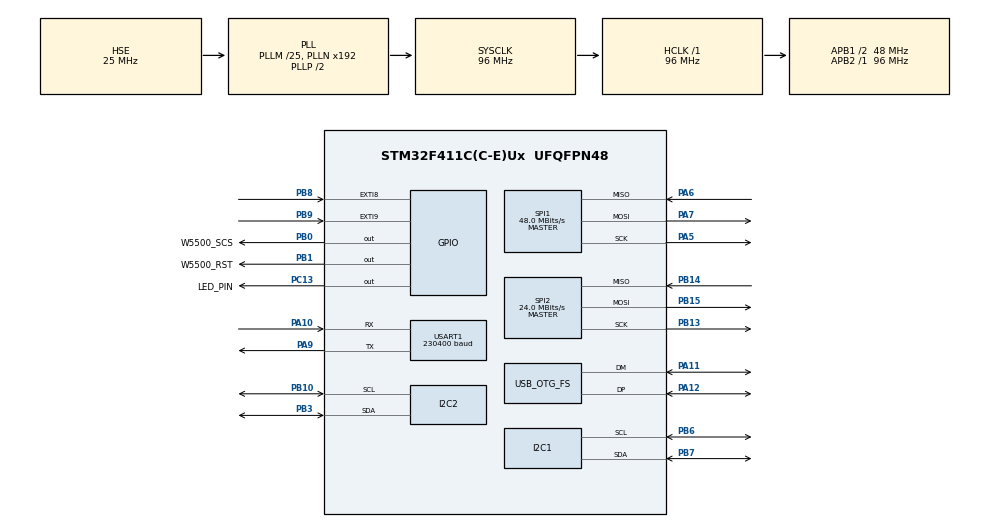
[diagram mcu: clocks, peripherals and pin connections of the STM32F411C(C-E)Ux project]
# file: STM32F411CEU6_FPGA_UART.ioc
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Dma.I2C1_TX.1.Direction=DMA_MEMORY_TO_PERIPH
Dma.I2C1_TX.1.FIFOMode=DMA_FIFOMODE_ENABLE
Dma.I2C1_TX.1.FIFOThreshold=DMA_FIFO_THRESHOLD_HALFFULL
Dma.I2C1_TX.1.Instance=DMA1_Stream1
Dma.I2C1_TX.1.MemBurst=DMA_MBURST_INC4
Dma.I2C1_TX.1.MemDataAlignment=DMA_MDATAALIGN_BYTE
Dma.I2C1_TX.1.MemInc=DMA_MINC_ENABLE
Dma.I2C1_TX.1.Mode=DMA_NORMAL
Dma.I2C1_TX.1.PeriphBurst=DMA_PBURST_SINGLE
Dma.I2C1_TX.1.PeriphDataAlignment=DMA_PDATAALIGN_BYTE
Dma.I2C1_TX.1.PeriphInc=DMA_PINC_DISABLE
Dma.I2C1_TX.1.Priority=DMA_PRIORITY_LOW
Dma.I2C2_TX.4.Direction=DMA_MEMORY_TO_PERIPH
Dma.I2C2_TX.4.FIFOMode=DMA_FIFOMODE_ENABLE
Dma.I2C2_TX.4.FIFOThreshold=DMA_FIFO_THRESHOLD_HALFFULL
Dma.I2C2_TX.4.Instance=DMA1_Stream7
Dma.I2C2_TX.4.MemBurst=DMA_MBURST_INC4
Dma.I2C2_TX.4.MemDataAlignment=DMA_MDATAALIGN_BYTE
Dma.I2C2_TX.4.MemInc=DMA_MINC_ENABLE
Dma.I2C2_TX.4.Mode=DMA_NORMAL
Dma.I2C2_TX.4.PeriphBurst=DMA_PBURST_SINGLE
Dma.I2C2_TX.4.PeriphDataAlignment=DMA_PDATAALIGN_BYTE
Dma.I2C2_TX.4.PeriphInc=DMA_PINC_DISABLE
Dma.I2C2_TX.4.Priority=DMA_PRIORITY_LOW
Dma.Request0=USART1_RX
Dma.Request1=I2C1_TX
Dma.Request2=SPI1_RX
Dma.Request3=SPI1_TX
Dma.Request4=I2C2_TX
Dma.Request5=SPI2_RX
Dma.Request6=SPI2_TX
Dma.SPI1_RX.2.Direction=DMA_PERIPH_TO_MEMORY
Dma.SPI1_RX.2.FIFOMode=DMA_FIFOMODE_DISABLE
Dma.SPI1_RX.2.Instance=DMA2_Stream0
Dma.SPI1_RX.2.MemDataAlignment=DMA_MDATAALIGN_BYTE
Dma.SPI1_RX.2.MemInc=DMA_MINC_ENABLE
Dma.SPI1_RX.2.Mode=DMA_NORMAL
Dma.SPI1_RX.2.PeriphDataAlignment=DMA_PDATAALIGN_BYTE
Dma.SPI1_RX.2.PeriphInc=DMA_PINC_DISABLE
Dma.SPI1_RX.2.Priority=DMA_PRIORITY_LOW
Dma.SPI1_TX.3.Direction=DMA_MEMORY_TO_PERIPH
Dma.SPI1_TX.3.FIFOMode=DMA_FIFOMODE_DISABLE
Dma.SPI1_TX.3.Instance=DMA2_Stream3
Dma.SPI1_TX.3.MemDataAlignment=DMA_MDATAALIGN_BYTE
Dma.SPI1_TX.3.MemInc=DMA_MINC_ENABLE
Dma.SPI1_TX.3.Mode=DMA_NORMAL
Dma.SPI1_TX.3.PeriphDataAlignment=DMA_PDATAALIGN_BYTE
Dma.SPI1_TX.3.PeriphInc=DMA_PINC_DISABLE
Dma.SPI1_TX.3.Priority=DMA_PRIORITY_LOW
Dma.SPI2_RX.5.Direction=DMA_PERIPH_TO_MEMORY
Dma.SPI2_RX.5.FIFOMode=DMA_FIFOMODE_DISABLE
Dma.SPI2_RX.5.Instance=DMA1_Stream3
Dma.SPI2_RX.5.MemDataAlignment=DMA_MDATAALIGN_BYTE
Dma.SPI2_RX.5.MemInc=DMA_MINC_ENABLE
Dma.SPI2_RX.5.Mode=DMA_NORMAL
Dma.SPI2_RX.5.PeriphDataAlignment=DMA_PDATAALIGN_BYTE
Dma.SPI2_RX.5.PeriphInc=DMA_PINC_DISABLE
Dma.SPI2_RX.5.Priority=DMA_PRIORITY_LOW
Dma.SPI2_TX.6.Direction=DMA_MEMORY_TO_PERIPH
Dma.SPI2_TX.6.FIFOMode=DMA_FIFOMODE_DISABLE
Dma.SPI2_TX.6.Instance=DMA1_Stream4
Dma.SPI2_TX.6.MemDataAlignment=DMA_MDATAALIGN_BYTE
Dma.SPI2_TX.6.MemInc=DMA_MINC_ENABLE
Dma.SPI2_TX.6.Mode=DMA_NORMAL
Dma.SPI2_TX.6.PeriphDataAlignment=DMA_PDATAALIGN_BYTE
Dma.SPI2_TX.6.PeriphInc=DMA_PINC_DISABLE
Dma.SPI2_TX.6.Priority=DMA_PRIORITY_LOW
Dma.USART1_RX.0.Direction=DMA_PERIPH_TO_MEMORY
Dma.USART1_RX.0.FIFOMode=DMA_FIFOMODE_ENABLE
Dma.USART1_RX.0.FIFOThreshold=DMA_FIFO_THRESHOLD_HALFFULL
Dma.USART1_RX.0.Instance=DMA2_Stream2
Dma.USART1_RX.0.MemBurst=DMA_MBURST_INC4
Dma.USART1_RX.0.MemDataAlignment=DMA_MDATAALIGN_BYTE
Dma.USART1_RX.0.MemInc=DMA_MINC_ENABLE
Dma.USART1_RX.0.Mode=DMA_CIRCULAR
Dma.USART1_RX.0.PeriphBurst=DMA_PBURST_SINGLE
Dma.USART1_RX.0.PeriphDataAlignment=DMA_PDATAALIGN_BYTE
Dma.USART1_RX.0.PeriphInc=DMA_PINC_DISABLE
Dma.USART1_RX.0.Priority=DMA_PRIORITY_LOW
I2C1.I2C_Mode=I2C_Fast
I2C2.I2C_Mode=I2C_Fast
Mcu.Family=STM32F4
Mcu.Name=STM32F411C(C-E)Ux
Mcu.Package=UFQFPN48
NVIC.DMA1_Stream1_IRQn=true\:0\:0\:false\:false\:true\:false\:true\:true
NVIC.DMA1_Stream3_IRQn=true\:0\:0\:false\:false\:true\:false\:true\:true
NVIC.DMA1_Stream4_IRQn=true\:0\:0\:false\:false\:true\:false\:true\:true
NVIC.DMA1_Stream7_IRQn=true\:0\:0\:false\:false\:true\:false\:true\:true
NVIC.DMA2_Stream0_IRQn=true\:0\:0\:false\:false\:true\:false\:true\:true
NVIC.DMA2_Stream2_IRQn=true\:0\:0\:false\:false\:true\:false\:true\:true
NVIC.DMA2_Stream3_IRQn=true\:0\:0\:false\:false\:true\:false\:true\:true
NVIC.EXTI9_5_IRQn=true\:0\:0\:false\:false\:true\:true\:true\:true
NVIC.I2C1_ER_IRQn=true\:0\:0\:false\:false\:true\:true\:true\:true
NVIC.I2C1_EV_IRQn=true\:0\:0\:false\:false\:true\:true\:true\:true
NVIC.I2C2_ER_IRQn=true\:0\:0\:false\:false\:true\:true\:true\:true
NVIC.I2C2_EV_IRQn=true\:0\:0\:false\:false\:true\:true\:true\:true
NVIC.OTG_FS_IRQn=true\:0\:0\:false\:false\:true\:false\:true\:true
NVIC.PriorityGroup=NVIC_PRIORITYGROUP_4
NVIC.SPI2_IRQn=true\:0\:0\:false\:false\:true\:true\:true\:true
NVIC.TIM1_BRK_TIM9_IRQn=true\:0\:0\:false\:false\:true\:true\:true\:true
NVIC.TIM1_CC_IRQn=true\:0\:0\:false\:false\:true\:true\:true\:true
NVIC.TIM1_TRG_COM_TIM11_IRQn=true\:0\:0\:false\:false\:true\:true\:true\:true
NVIC.TIM1_UP_TIM10_IRQn=true\:0\:0\:false\:false\:true\:true\:true\:true
NVIC.USART1_IRQn=true\:0\:0\:false\:false\:true\:true\:true\:true
PA10.Mode=Asynchronous
PA10.Signal=USART1_RX
PA11.Mode=Device_Only
PA11.Signal=USB_OTG_FS_DM
PA12.Mode=Device_Only
PA12.Signal=USB_OTG_FS_DP
PA13.Mode=Serial_Wire
PA13.Signal=SYS_JTMS-SWDIO
PA14.Mode=Serial_Wire
PA14.Signal=SYS_JTCK-SWCLK
PA5.Mode=Full_Duplex_Master
PA5.Signal=SPI1_SCK
PA6.Mode=Full_Duplex_Master
PA6.Signal=SPI1_MISO
PA7.Mode=Full_Duplex_Master
PA7.Signal=SPI1_MOSI
PA9.Mode=Asynchronous
PA9.Signal=USART1_TX
PB0.GPIO_Label=W5500_SCS
PB0.GPIO_ModeDefaultOutputPP=GPIO_MODE_OUTPUT_PP
PB0.GPIO_Speed=GPIO_SPEED_FREQ_VERY_HIGH
PB0.PinState=GPIO_PIN_SET
PB0.Signal=GPIO_Output
PB1.GPIO_Label=W5500_RST
PB1.GPIO_Speed=GPIO_SPEED_FREQ_VERY_HIGH
PB1.PinState=GPIO_PIN_SET
PB1.Signal=GPIO_Output
PB10.Mode=I2C
PB10.Signal=I2C2_SCL
PB13.Mode=Full_Duplex_Master
PB13.Signal=SPI2_SCK
PB14.Mode=Full_Duplex_Master
PB14.Signal=SPI2_MISO
PB15.Mode=Full_Duplex_Master
PB15.Signal=SPI2_MOSI
PB3.Mode=I2C
PB3.Signal=I2C2_SDA
PB6.Mode=I2C
PB6.Signal=I2C1_SCL
PB7.Mode=I2C
PB7.Signal=I2C1_SDA
PB8.GPIO_ModeDefaultEXTI=GPIO_MODE_IT_RISING_FALLING
PB8.Signal=GPXTI8
PB9.GPIO_ModeDefaultEXTI=GPIO_MODE_IT_RISING_FALLING
PB9.Signal=GPXTI9
PC13-ANTI_TAMP.GPIO_Label=LED_PIN
PC13-ANTI_TAMP.GPIO_ModeDefaultOutputPP=GPIO_MODE_OUTPUT_OD
PC13-ANTI_TAMP.Signal=GPIO_Output
PC14-OSC32_IN.Mode=LSE-External-Oscillator
PC14-OSC32_IN.Signal=RCC_OSC32_IN
PC15-OSC32_OUT.Mode=LSE-External-Oscillator
PC15-OSC32_OUT.Signal=RCC_OSC32_OUT
PH0\ -\ OSC_IN.Mode=HSE-External-Oscillator
PH0\ -\ OSC_IN.Signal=RCC_OSC_IN
PH1\ -\ OSC_OUT.Mode=HSE-External-Oscillator
PH1\ -\ OSC_OUT.Signal=RCC_OSC_OUT
ProjectManager.HeapSize=0x200
ProjectManager.StackSize=0x400
ProjectManager.TargetToolchain=STM32CubeIDE
RCC.48MHZClocksFreq_Value=48000000
RCC.AHBFreq_Value=96000000
RCC.APB1CLKDivider=RCC_HCLK_DIV2
RCC.APB1Freq_Value=48000000
RCC.APB1TimFreq_Value=96000000
RCC.APB2Freq_Value=96000000
RCC.APB2TimFreq_Value=96000000
RCC.CortexFreq_Value=96000000
RCC.HCLKFreq_Value=96000000
RCC.HSE_VALUE=25000000
RCC.HSI_VALUE=16000000
RCC.PLLM=25
RCC.SYSCLKFreq_VALUE=96000000
RCC.SYSCLKSource=RCC_SYSCLKSOURCE_PLLCLK
RCC.VCOOutputFreq_Value=192000000
SPI1.BaudRatePrescaler=SPI_BAUDRATEPRESCALER_2
SPI1.CalculateBaudRate=48.0 MBits/s
SPI1.Direction=SPI_DIRECTION_2LINES
SPI1.Mode=SPI_MODE_MASTER
SPI1.VirtualType=VM_MASTER
SPI2.CalculateBaudRate=24.0 MBits/s
SPI2.Direction=SPI_DIRECTION_2LINES
SPI2.Mode=SPI_MODE_MASTER
SPI2.VirtualType=VM_MASTER
TIM1.Period=999
TIM1.Prescaler=95
USART1.BaudRate=230400
USART1.VirtualMode=VM_ASYNC
USB_DEVICE.CLASS_NAME_FS=CUSTOM_HID
USB_DEVICE.MANUFACTURER_STRING=Maksym Veremeyenko
USB_DEVICE.PID_CUSTOMHID_FS=0x16c0
USB_DEVICE.PRODUCT_STRING_CUSTOMHID_FS=Lens Rotary Decoder UDP module/ https\://github.com/max-verem/LensRotaryDecoder
USB_DEVICE.USBD_CUSTOMHID_OUTREPORT_BUF_SIZE=8
USB_DEVICE.USBD_CUSTOM_HID_REPORT_DESC_SIZE=8
USB_DEVICE.VID=0x05df
USB_DEVICE.VirtualMode=CustomHid
USB_DEVICE.VirtualModeFS=Custom_Hid_FS
USB_OTG_FS.VirtualMode=Device_Only
VP_TIM1_VS_ClockSourceINT.Mode=Internal
VP_USB_DEVICE_VS_USB_DEVICE_CUSTOM_HID_FS.Mode=CUSTOM_HID_FS
board=custom

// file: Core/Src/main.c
/* USER CODE BEGIN Header */
/**
  ******************************************************************************
  * @file           : main.c
  * @brief          : Main program body
  ******************************************************************************
  * @attention
  *
  * <h2><center>&copy; Copyright (c) 2021 STMicroelectronics.
  * All rights reserved.</center></h2>
  *
  * This software component is licensed by ST under BSD 3-Clause license,
  * the "License"; You may not use this file except in compliance with the
  * License. You may obtain a copy of the License at:
  *                        opensource.org/licenses/BSD-3-Clause
  *
  ******************************************************************************
  */
/* USER CODE END Header */
#include "main.h"
#include "usb_device.h"

/* USER CODE BEGIN Includes */
#include "app.h"
#include "usbd_customhid.h"
/* USER CODE END Includes */

I2C_HandleTypeDef hi2c1;
I2C_HandleTypeDef hi2c2;
DMA_HandleTypeDef hdma_i2c1_tx;
DMA_HandleTypeDef hdma_i2c2_tx;

SPI_HandleTypeDef hspi1;
SPI_HandleTypeDef hspi2;
DMA_HandleTypeDef hdma_spi1_rx;
DMA_HandleTypeDef hdma_spi1_tx;
DMA_HandleTypeDef hdma_spi2_rx;
DMA_HandleTypeDef hdma_spi2_tx;

TIM_HandleTypeDef htim1;

UART_HandleTypeDef huart1;
DMA_HandleTypeDef hdma_usart1_rx;

void SystemClock_Config(void);
static void MX_GPIO_Init(void);
static void MX_DMA_Init(void);
static void MX_USART1_UART_Init(void);
static void MX_I2C1_Init(void);
static void MX_SPI1_Init(void);
static void MX_I2C2_Init(void);
static void MX_TIM1_Init(void);
static void MX_SPI2_Init(void);

/* USER CODE BEGIN 0 */

// ---------------------------------------------------

#ifdef DEBUG123

#include <stdio.h>
#include <errno.h>
//#include  <sys/unistd.h> // STDOUT_FILENO, STDERR_FILENO

int _write(int file, char *data, int len)
{
   // arbitrary timeout 1000
   HAL_StatusTypeDef status =
      HAL_UART_Transmit(&huart1, (uint8_t*)data, len, 1000);

   // return # of bytes written - as best we can tell
   return (status == HAL_OK ? len : 0);
}

#endif

// ---------------------------------------------------

/* USER CODE END 0 */

int main(void)
{

  /* MCU Configuration--------------------------------------------------------*/

  /* Reset of all peripherals, Initializes the Flash interface and the Systick. */
  HAL_Init();

  /* USER CODE BEGIN Init */
  app_init();
  /* USER CODE END Init */

  /* Configure the system clock */
  SystemClock_Config();

  /* Initialize all configured peripherals */
  MX_GPIO_Init();
  MX_DMA_Init();
  MX_USB_DEVICE_Init();
  MX_USART1_UART_Init();
  MX_I2C1_Init();
  MX_SPI1_Init();
  MX_I2C2_Init();
  MX_TIM1_Init();
  MX_SPI2_Init();
  /* USER CODE BEGIN 2 */
  app_begin();
  /* USER CODE END 2 */

  /* Infinite loop */
  /* USER CODE BEGIN WHILE */
  while (1)
  {
	app_loop();
    /* USER CODE END WHILE */

  }
}

void SystemClock_Config(void)
{
  RCC_OscInitTypeDef RCC_OscInitStruct = {0};
  RCC_ClkInitTypeDef RCC_ClkInitStruct = {0};

  /** Configure the main internal regulator output voltage
  */
  __HAL_RCC_PWR_CLK_ENABLE();
  __HAL_PWR_VOLTAGESCALING_CONFIG(PWR_REGULATOR_VOLTAGE_SCALE1);

  /** Initializes the RCC Oscillators according to the specified parameters
  * in the RCC_OscInitTypeDef structure.
  */
  RCC_OscInitStruct.OscillatorType = RCC_OSCILLATORTYPE_HSE;
  RCC_OscInitStruct.HSEState = RCC_HSE_ON;
  RCC_OscInitStruct.PLL.PLLState = RCC_PLL_ON;
  RCC_OscInitStruct.PLL.PLLSource = RCC_PLLSOURCE_HSE;
  RCC_OscInitStruct.PLL.PLLM = 25;
  RCC_OscInitStruct.PLL.PLLN = 192;
  RCC_OscInitStruct.PLL.PLLP = RCC_PLLP_DIV2;
  RCC_OscInitStruct.PLL.PLLQ = 4;
  if (HAL_RCC_OscConfig(&RCC_OscInitStruct) != HAL_OK)
  {
    Error_Handler();
  }

  /** Initializes the CPU, AHB and APB buses clocks
  */
  RCC_ClkInitStruct.ClockType = RCC_CLOCKTYPE_HCLK|RCC_CLOCKTYPE_SYSCLK
                              |RCC_CLOCKTYPE_PCLK1|RCC_CLOCKTYPE_PCLK2;
  RCC_ClkInitStruct.SYSCLKSource = RCC_SYSCLKSOURCE_PLLCLK;
  RCC_ClkInitStruct.AHBCLKDivider = RCC_SYSCLK_DIV1;
  RCC_ClkInitStruct.APB1CLKDivider = RCC_HCLK_DIV2;
  RCC_ClkInitStruct.APB2CLKDivider = RCC_HCLK_DIV1;

  if (HAL_RCC_ClockConfig(&RCC_ClkInitStruct, FLASH_LATENCY_3) != HAL_OK)
  {
    Error_Handler();
  }
}

static void MX_I2C1_Init(void)
{

  hi2c1.Instance = I2C1;
  hi2c1.Init.ClockSpeed = 400000;
  hi2c1.Init.DutyCycle = I2C_DUTYCYCLE_2;
  hi2c1.Init.OwnAddress1 = 0;
  hi2c1.Init.AddressingMode = I2C_ADDRESSINGMODE_7BIT;
  hi2c1.Init.DualAddressMode = I2C_DUALADDRESS_DISABLE;
  hi2c1.Init.OwnAddress2 = 0;
  hi2c1.Init.GeneralCallMode = I2C_GENERALCALL_DISABLE;
  hi2c1.Init.NoStretchMode = I2C_NOSTRETCH_DISABLE;
  if (HAL_I2C_Init(&hi2c1) != HAL_OK)
  {
    Error_Handler();
  }

}

static void MX_I2C2_Init(void)
{

  hi2c2.Instance = I2C2;
  hi2c2.Init.ClockSpeed = 400000;
  hi2c2.Init.DutyCycle = I2C_DUTYCYCLE_2;
  hi2c2.Init.OwnAddress1 = 0;
  hi2c2.Init.AddressingMode = I2C_ADDRESSINGMODE_7BIT;
  hi2c2.Init.DualAddressMode = I2C_DUALADDRESS_DISABLE;
  hi2c2.Init.OwnAddress2 = 0;
  hi2c2.Init.GeneralCallMode = I2C_GENERALCALL_DISABLE;
  hi2c2.Init.NoStretchMode = I2C_NOSTRETCH_DISABLE;
  if (HAL_I2C_Init(&hi2c2) != HAL_OK)
  {
    Error_Handler();
  }

}

static void MX_SPI1_Init(void)
{

  /* SPI1 parameter configuration*/
  hspi1.Instance = SPI1;
  hspi1.Init.Mode = SPI_MODE_MASTER;
  hspi1.Init.Direction = SPI_DIRECTION_2LINES;
  hspi1.Init.DataSize = SPI_DATASIZE_8BIT;
  hspi1.Init.CLKPolarity = SPI_POLARITY_LOW;
  hspi1.Init.CLKPhase = SPI_PHASE_1EDGE;
  hspi1.Init.NSS = SPI_NSS_SOFT;
  hspi1.Init.BaudRatePrescaler = SPI_BAUDRATEPRESCALER_2;
  hspi1.Init.FirstBit = SPI_FIRSTBIT_MSB;
  hspi1.Init.TIMode = SPI_TIMODE_DISABLE;
  hspi1.Init.CRCCalculation = SPI_CRCCALCULATION_DISABLE;
  hspi1.Init.CRCPolynomial = 10;
  if (HAL_SPI_Init(&hspi1) != HAL_OK)
  {
    Error_Handler();
  }

}

static void MX_SPI2_Init(void)
{

  /* SPI2 parameter configuration*/
  hspi2.Instance = SPI2;
  hspi2.Init.Mode = SPI_MODE_MASTER;
  hspi2.Init.Direction = SPI_DIRECTION_2LINES;
  hspi2.Init.DataSize = SPI_DATASIZE_8BIT;
  hspi2.Init.CLKPolarity = SPI_POLARITY_LOW;
  hspi2.Init.CLKPhase = SPI_PHASE_1EDGE;
  hspi2.Init.NSS = SPI_NSS_SOFT;
  hspi2.Init.BaudRatePrescaler = SPI_BAUDRATEPRESCALER_2;
  hspi2.Init.FirstBit = SPI_FIRSTBIT_MSB;
  hspi2.Init.TIMode = SPI_TIMODE_DISABLE;
  hspi2.Init.CRCCalculation = SPI_CRCCALCULATION_DISABLE;
  hspi2.Init.CRCPolynomial = 10;
  if (HAL_SPI_Init(&hspi2) != HAL_OK)
  {
    Error_Handler();
  }

}

static void MX_TIM1_Init(void)
{

  TIM_ClockConfigTypeDef sClockSourceConfig = {0};
  TIM_MasterConfigTypeDef sMasterConfig = {0};

  htim1.Instance = TIM1;
  htim1.Init.Prescaler = 95;
  htim1.Init.CounterMode = TIM_COUNTERMODE_UP;
  htim1.Init.Period = 999;
  htim1.Init.ClockDivision = TIM_CLOCKDIVISION_DIV1;
  htim1.Init.RepetitionCounter = 0;
  htim1.Init.AutoReloadPreload = TIM_AUTORELOAD_PRELOAD_DISABLE;
  if (HAL_TIM_Base_Init(&htim1) != HAL_OK)
  {
    Error_Handler();
  }
  sClockSourceConfig.ClockSource = TIM_CLOCKSOURCE_INTERNAL;
  if (HAL_TIM_ConfigClockSource(&htim1, &sClockSourceConfig) != HAL_OK)
  {
    Error_Handler();
  }
  sMasterConfig.MasterOutputTrigger = TIM_TRGO_RESET;
  sMasterConfig.MasterSlaveMode = TIM_MASTERSLAVEMODE_DISABLE;
  if (HAL_TIMEx_MasterConfigSynchronization(&htim1, &sMasterConfig) != HAL_OK)
  {
    Error_Handler();
  }

}

static void MX_USART1_UART_Init(void)
{

  huart1.Instance = USART1;
  huart1.Init.BaudRate = 230400;
  huart1.Init.WordLength = UART_WORDLENGTH_8B;
  huart1.Init.StopBits = UART_STOPBITS_1;
  huart1.Init.Parity = UART_PARITY_NONE;
  huart1.Init.Mode = UART_MODE_TX_RX;
  huart1.Init.HwFlowCtl = UART_HWCONTROL_NONE;
  huart1.Init.OverSampling = UART_OVERSAMPLING_16;
  if (HAL_UART_Init(&huart1) != HAL_OK)
  {
    Error_Handler();
  }

}

static void MX_DMA_Init(void)
{

  /* DMA controller clock enable */
  __HAL_RCC_DMA2_CLK_ENABLE();
  __HAL_RCC_DMA1_CLK_ENABLE();

  /* DMA interrupt init */
  /* DMA1_Stream1_IRQn interrupt configuration */
  HAL_NVIC_SetPriority(DMA1_Stream1_IRQn, 0, 0);
  HAL_NVIC_EnableIRQ(DMA1_Stream1_IRQn);
  /* DMA1_Stream3_IRQn interrupt configuration */
  HAL_NVIC_SetPriority(DMA1_Stream3_IRQn, 0, 0);
  HAL_NVIC_EnableIRQ(DMA1_Stream3_IRQn);
  /* DMA1_Stream4_IRQn interrupt configuration */
  HAL_NVIC_SetPriority(DMA1_Stream4_IRQn, 0, 0);
  HAL_NVIC_EnableIRQ(DMA1_Stream4_IRQn);
  /* DMA1_Stream7_IRQn interrupt configuration */
  HAL_NVIC_SetPriority(DMA1_Stream7_IRQn, 0, 0);
  HAL_NVIC_EnableIRQ(DMA1_Stream7_IRQn);
  /* DMA2_Stream0_IRQn interrupt configuration */
  HAL_NVIC_SetPriority(DMA2_Stream0_IRQn, 0, 0);
  HAL_NVIC_EnableIRQ(DMA2_Stream0_IRQn);
  /* DMA2_Stream2_IRQn interrupt configuration */
  HAL_NVIC_SetPriority(DMA2_Stream2_IRQn, 0, 0);
  HAL_NVIC_EnableIRQ(DMA2_Stream2_IRQn);
  /* DMA2_Stream3_IRQn interrupt configuration */
  HAL_NVIC_SetPriority(DMA2_Stream3_IRQn, 0, 0);
  HAL_NVIC_EnableIRQ(DMA2_Stream3_IRQn);

}

static void MX_GPIO_Init(void)
{
  GPIO_InitTypeDef GPIO_InitStruct = {0};

  /* GPIO Ports Clock Enable */
  __HAL_RCC_GPIOC_CLK_ENABLE();
  __HAL_RCC_GPIOH_CLK_ENABLE();
  __HAL_RCC_GPIOA_CLK_ENABLE();
  __HAL_RCC_GPIOB_CLK_ENABLE();

  /*Configure GPIO pin Output Level */
  HAL_GPIO_WritePin(LED_PIN_GPIO_Port, LED_PIN_Pin, GPIO_PIN_RESET);

  /*Configure GPIO pin Output Level */
  HAL_GPIO_WritePin(GPIOB, W5500_SCS_Pin|W5500_RST_Pin, GPIO_PIN_SET);

  /*Configure GPIO pin : LED_PIN_Pin */
  GPIO_InitStruct.Pin = LED_PIN_Pin;
  GPIO_InitStruct.Mode = GPIO_MODE_OUTPUT_OD;
  GPIO_InitStruct.Pull = GPIO_NOPULL;
  GPIO_InitStruct.Speed = GPIO_SPEED_FREQ_LOW;
  HAL_GPIO_Init(LED_PIN_GPIO_Port, &GPIO_InitStruct);

  /*Configure GPIO pins : W5500_SCS_Pin W5500_RST_Pin */
  GPIO_InitStruct.Pin = W5500_SCS_Pin|W5500_RST_Pin;
  GPIO_InitStruct.Mode = GPIO_MODE_OUTPUT_PP;
  GPIO_InitStruct.Pull = GPIO_NOPULL;
  GPIO_InitStruct.Speed = GPIO_SPEED_FREQ_VERY_HIGH;
  HAL_GPIO_Init(GPIOB, &GPIO_InitStruct);

  /*Configure GPIO pins : PB8 PB9 */
  GPIO_InitStruct.Pin = GPIO_PIN_8|GPIO_PIN_9;
  GPIO_InitStruct.Mode = GPIO_MODE_IT_RISING_FALLING;
  GPIO_InitStruct.Pull = GPIO_NOPULL;
  HAL_GPIO_Init(GPIOB, &GPIO_InitStruct);

  /* EXTI interrupt init*/
  HAL_NVIC_SetPriority(EXTI9_5_IRQn, 0, 0);
  HAL_NVIC_EnableIRQ(EXTI9_5_IRQn);

}

void Error_Handler(void)
{
  __disable_irq();
  while (1)
  {
  }
}
